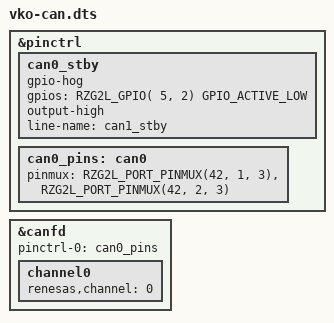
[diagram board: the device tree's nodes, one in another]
/*
 * Copyright 2023 Vekatech
 *
 * This program is free software; you can redistribute it and/or
 * modify it under the terms of the GNU General Public License
 * as published by the Free Software Foundation; either version 2
 * of the License, or (at your option) any later version.
 *
 * This program is distributed in the hope that it will be useful,
 * but WITHOUT ANY WARRANTY; without even the implied warranty of
 * MERCHANTABILITY or FITNESS FOR A PARTICULAR PURPOSE. See the
 * GNU General Public License for more details.
 */

/dts-v1/;
/plugin/;

#include <dt-bindings/pinctrl/rzg2l-pinctrl.h>
#include <dt-bindings/gpio/gpio.h>

&pinctrl {
	can0_stby {
		gpio-hog;
		gpios = <RZG2L_GPIO( 5, 2) GPIO_ACTIVE_LOW>;
		output-high;
		line-name = "can1_stby";
	};

	can0_pins: can0 {
		pinmux = <RZG2L_PORT_PINMUX(42, 1, 3)>, /* TX */
			 <RZG2L_PORT_PINMUX(42, 2, 3)>; /* RX */
	};
};

&canfd {
	pinctrl-0 = <&can0_pins>;
	pinctrl-names = "default";
	status = "okay";

	/* Default set as Classical CAN(CAN 2.0) mode, remove to enable CAN FD mode */
	/*renesas,no-can-fd;*/

	channel0 {
		renesas,channel = <0>;
		status = "okay";
	};
};

